# RL6955_IP_SVD register map
Vendor: Realtek
Registers are 32-bit, read-write, reset 0x0 unless marked. A register's access mark holds for its fields unless they carry their own. Offsets are from the block's base; [hi:lo] are bit positions; {n}, {i} and the like mark numbered series; <NAME> marks a mode.

## I3C_REG
Base 0x41890000
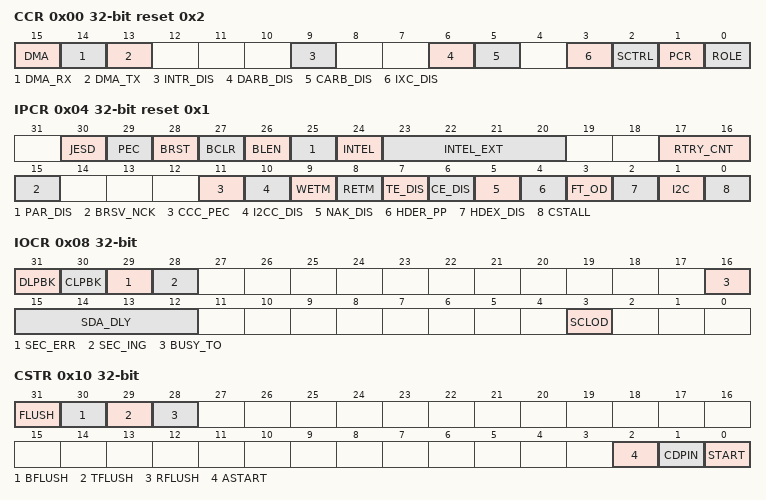
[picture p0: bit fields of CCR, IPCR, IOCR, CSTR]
0x00 CCR access per field reset 0x2 — Configuration Control Register
  [15] DMA wo — DMAC handshake interface support Exists: TAG >= 2.2.1
  [14] DMA_RX wo — DMAC handshake TX enable Exists: TAG >= 2.2.1
  [13] DMA_TX wo — DMAC handshake RX enable Exists: TAG >= 2.2.1
  [9] INTR_DIS rw — Interrupt global disable
  [6] DARB_DIS rw
  [5] CARB_DIS rw
  [3] IXC_DIS rw — IXC IP disable 1 = disable 0 = enable
  [2] SCTRL rw — Secondary Control mode enable for CCR.ROLE=TAGT.Only Can be set 1 when config I3CC_SCTRL = 1 in config form file, otherwise this bit would be always 0.
  [1] PCR rw — 1: Primary Control 0: Not Primary Control
  [0] ROLE rw — Role of the rxi356_i3cc Write: 0 - Role is the primary controller 1 - Role is the target Read: 0 - Role is the Active controller 1 - Role is the target
0x04 IPCR access per field reset 0x1 — I3C/I2C protocol control Register
  [30] JESD rw — JESD Spec enable
  [29] PEC rw — PEC CRC enable. Can be enable when INTEL = 1 or JESD =1 .
  [28] BRST rw — Bus Reset (TimedReset) enable. Can be enable when INTEL = 1 or JESD =1 .
  [27] BCLR rw — Bus Clear Enable. Can be enable when INTEL = 1 or JESD =1 .
  [26] BLEN rw — BL Enable for Intel Spec
  [25] PAR_DIS rw — Parity Check Disable (Can be disable when INTEL = 1 or JESD = 1).
  [24] INTEL rw — INTEL Spec enable
  [23:20] INTEL_EXT rw — Intel spec extend bit 23: intel_ddr : 0 (disable) / 1 (enable) bit 22: intel_as : 0 (disable) / 1 (enable) bit 21: intel_ccc : 0 (disable) / 1 (enable) bit 20: intel_ga : 0 (disable) / 1 (enable)
  [17:16] RTRY_CNT rw — Read Retry Count for ROLE = CTRL. RTRY_CNTretry numberTotal read cmd count 2'b00: No retry, total read cmd count=1 2'b01: Retry 1 time, total read cmd count=2 2'b10: Retry 2 times, total read cmd count=3 2'b11: Retry 3 times, total read cmd count=4
  [15] BRSV_NCK rw — Reserved
  [11] CCC_PEC rw — 1: Direct CCC cmd must includes pec byte, otherwise the pec_err & intr_pece would toggle. 0: disable this feature (just for INTEL = 1), direct CCC cmd without PEC byte would be acceptted as normal cmd, and the the pec_err & intr_pece would Not come out.
  [10] I2CC_DIS rw — for TAGT: NACK I2C private access. Maybe used in CTS 2.1.9 test.
  [9] WETM wo — Write Early terminate, not supported Now
  [8] RETM rw — Read Early terminate, not supported Now
  [7] TE_DIS rw — TAGT ERROR Disable
  [6] CE_DIS wo — CTRL ERROR Disable
  [5] NAK_DIS rw — RX NACK Disable
  [4] HDER_PP rw — Enable Header Address turn to PP timing
  [3] FT_OD rw — Force Timing = OD
  [2] HDEX_DIS rw — HDR EXIT Pattern Disable
  [1] I2C rw — I2C BUS enable
  [0] CSTALL rw — SCL STALL feature enable. Now always enable. (reserved)
0x08 IOCR — I/O Configuration Control Register
  [31] DLPBK — SDA loop back calibration function enable
  [30] CLPBK — SCL loop back calibration function enable
  [29] SEC_ERR — Indicated for I3C Secondary Controller Handoff Procedure occured an error.
  [28] SEC_ING — Indicated for I3C Secondary Controller Handoff Procedure is going.
  [16] BUSY_TO — Indicated to turn to idle phase when SCL, SDA hold for tIDLE
  [15:12] SDA_DLY — Indicated SDA delay count Valid value: 0~4; others reserved Exists: TAG >= 2.0.3
  [3] SCLOD — Force output: SCL in Open-Drain Status.
0x10 CSTR access per field — Control Structure register
  [31] FLUSH ro — Flush BYFM/TXDA/RXDA & recovery ixc status
  [30] BFLUSH ro — Flush BYFM FIFO
  [29] TFLUSH ro — Flush TXDA FIFO
  [28] RFLUSH ro — Flush RXDA/RCMD FIFO
  [2] ASTART rw — Control strucure async mode0 flow start
  [1] CDPIN rw — CDPin start Exists: TAG >= 2.0.2
  [0] START rw — Control strucure flow start
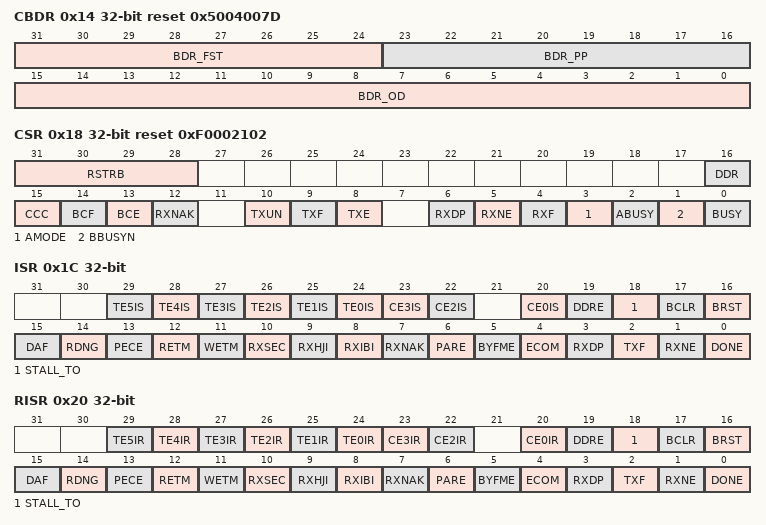
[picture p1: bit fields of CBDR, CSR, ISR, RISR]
0x14 CBDR reset 0x5004007D — SCL baud rate register
  [31:24] BDR_FST — Baud rate for the first header address
  [23:16] BDR_PP — Baud rate for PP
  [15:0] BDR_OD — Baud rate for OD
0x18 CSR access per field reset 0xF0002102 — Current Status Register
  [31:28] RSTRB ro — APB read strob Available value: 0x0, 0x1, 0x3, 0x7, 0xf
  [16] DDR ro — HDR-DDR mode
  [15] CCC ro — For target: receive a CCC cmd
  [14] BCF ro — BYFM CMD FIFO Full
  [13] BCE ro — BYFM CMD FIFO Empty
  [12] RXNAK ro — Received NACK
  [10] TXUN ro — TXDA Underflow (reserved)
  [9] TXF ro — TXDA Full
  [8] TXE ro — TXDA EMPTY
  [6] RXDP ro — RX DATA Drop
  [5] RXNE ro — RXDA Not Empty
  [4] RXF ro — RXDA Full
  [3] AMODE rw — In Async mode0 Only can be programmed in ctrl mode, user set AMODE=1 to enter asyn mode0 and set AMODE=0 to exit asyn mode0
  [2] ABUSY ro — 1: Async mode0 flow is still busy (action Not Over) 0: Async mode0 flow is Not busy
  [1] BBUSYN ro — BBUSYN = 1: IXC Bus is NOT Busy (Idle). Bus has detected Stop.BBUSYN= 0: IXC Bus is Busy. Bus has detected Start.
  [0] BUSY ro — 1: I3C/I2C transaction is still busy 0: I3C/I2C transaction is NOT busy (Idle)
0x1C ISR ro — Interrupt Status Register
  [n+24] TE{n}IS (n=0..5) — SDR target error type {n}
  [23] CE3IS — SDR controller error type 3
  [22] CE2IS — SDR controller error type 2
  [20] CE0IS — SDR controller error type 0
  [19] DDRE — DDR preamble, parity, CRC error
  [18] STALL_TO — For CTRL mode: SCL stall Timeout For TAGT mode: BUS busy Timeout
  [17] BCLR — Bus Clear
  [16] BRST — Bus Reset (TimedReset)
  [15] DAF — SDA arbitration fail
  [14] RDNG — Read RXDA word-unalign
  [13] PECE — PEC CRC Error
  [12] RETM — Read early terminate Occur
  [11] WETM — Write early terminate Occur
  [10] RXSEC — Receive Role REQ for ROLE=CTRL, or Received CCC GETACCCR for ROLE=SCTRL.
  [9] RXHJI — Receive Hot Join REQ
  [8] RXIBI — Receive IBI REQ
  [7] RXNAK — Receive NACK
  [6] PARE — PAR-bit Error For SDR mode: GETACCCR Format 3 (Role CTRL) ; TE1/2/3 For HDR mode: HDR-DDR transaction parity error
  [5] BYFME — BYFM Error
  [4] ECOM — Early COMplete transaction
  [3] RXDP — RX Data Drop occur for Role TAGT Case 1: Controller send write transcation with byte length exceed MWL. Case 2: Controller send write transcation meet RXDA_FIFO full
  [2] TXF — TXDA Full
  [1] RXNE — RXDA Not Empty
  [0] DONE — I3C/I2C transation is done
0x20 RISR ro — Raw Interrupt Status Register
  [n+24] TE{n}IR (n=0..5)
  [23] CE3IR
  [22] CE2IR
  [20] CE0IR
  [19] DDRE
  [18] STALL_TO
  [17] BCLR — Bus Clear
  [16] BRST — Bus Reset (TimedReset)
  [15] DAF
  [14] RDNG
  [13] PECE — PEC CRC Error
  [12] RETM
  [11] WETM
  [10] RXSEC
  [9] RXHJI
  [8] RXIBI
  [7] RXNAK
  [6] PARE
  [5] BYFME
  [4] ECOM
  [3] RXDP
  [2] TXF
  [1] RXNE
  [0] DONE
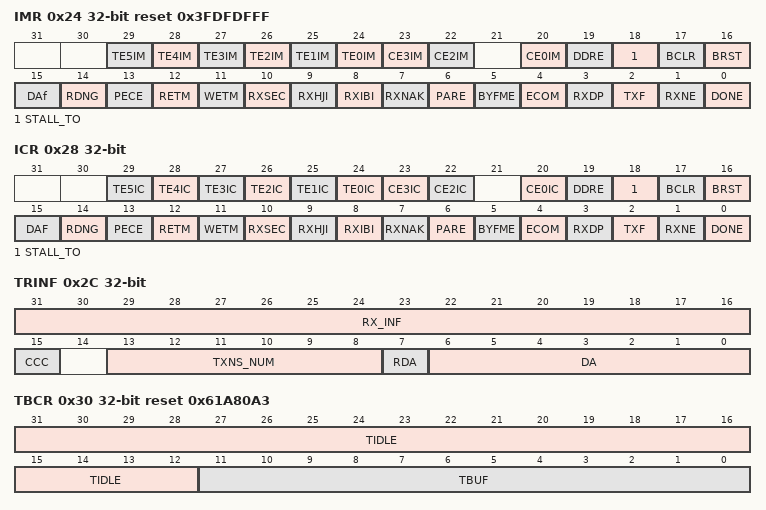
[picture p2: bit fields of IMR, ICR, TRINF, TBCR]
0x24 IMR reset 0x3FDFDFFF — Interrupt Mask Register
  [n+24] TE{n}IM (n=0..5)
  [23] CE3IM
  [22] CE2IM
  [20] CE0IM
  [19] DDRE
  [18] STALL_TO
  [17] BCLR — Bus Clear
  [16] BRST — Bus Reset (TimedReset)
  [15] DAf
  [14] RDNG
  [13] PECE — PEC CRC Error
  [12] RETM
  [11] WETM
  [10] RXSEC
  [9] RXHJI
  [8] RXIBI
  [7] RXNAK
  [6] PARE
  [5] BYFME
  [4] ECOM
  [3] RXDP
  [2] TXF
  [1] RXNE
  [0] DONE
0x28 ICR wo — Interrupt Clear Register
  [n+24] TE{n}IC (n=0..5)
  [23] CE3IC
  [22] CE2IC
  [20] CE0IC
  [19] DDRE
  [18] STALL_TO
  [17] BCLR — Bus Clear
  [16] BRST — Bus Reset (TimedReset)
  [15] DAF
  [14] RDNG
  [13] PECE — PEC CRC Error
  [12] RETM
  [11] WETM
  [10] RXSEC
  [9] RXHJI
  [8] RXIBI
  [7] RXNAK
  [6] PARE
  [5] BYFME
  [4] ECOM
  [3] RXDP
  [2] TXF
  [1] RXNE
  [0] DONE
0x2C TRINF ro — Transcation Information Register
  [31:16] RX_INF — [31:24]: for TAGT, receive CCC_CMD; for CTRL, receive IBI_MDB [23:16]: for TAGT, reveive CCC.defining byte; for CTRL, reserved
  [15] CCC — For target: receive a CCC cmd
  [13:8] TXNS_NUM — Transaction number for ROLE Ctrl
  [7] RDA — For TAGT, HDR-DDR req's RnW. For CTRL, IBI/HJ/SEC req's RnW.
  [6:0] DA — For TAGT, HDR-DDR command code. For CTRL, IBI/HJ/SEC req's DA.
0x30 TBCR reset 0x61A80A3 — BUS timing register
  [31:12] TIDLE — Bus IDLE Timing (tIDLE) count
  [11:0] TBUF — Bus Free Timing (tBUF) count
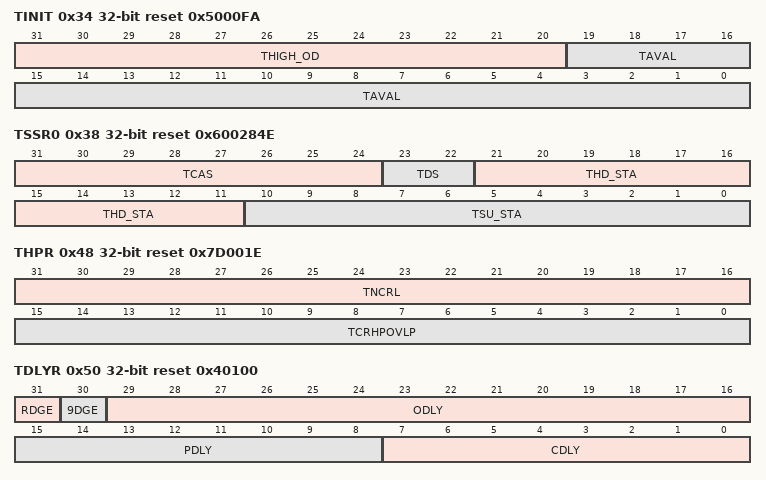
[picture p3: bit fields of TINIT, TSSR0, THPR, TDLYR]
0x34 TINIT reset 0x5000FA — Initial timing register
  [31:20] THIGH_OD — SCL High count for OD timing
  [19:0] TAVAL — Bus Available Timing (tAVAL) count
0x38 TSSR0 reset 0x600284E — Timing START register0
  [31:24] TCAS — tCAS timing count
  [23:22] TDS — tDS timing count Available value: 2'b00 ~ 2'b11
  [21:11] THD_STA — tHD_STA timing count
  [10:0] TSU_STA — tSU_STA timing count
0x3C TSSR1 reset 0x5 — Timing STOP register1
  [11:0] TSU_STO — tSU_STO timing count
0x40 TSTMR reset 0x30D4 — Reserved
  [31:0] TSTA_TO — Timeout count for pulling SCL=Low when SDA is Low at SEC HP flow.
0x44 TDR — Reserved
  [31:16] TSTALL_TO — Timeout count for SCL stall. Timeout = TSTALL_TO*32. Set 0 disable SCL stall timeout. ex. set 1 => timeout occur when counter count 32T
0x48 THPR reset 0x7D001E — Reserved
  [31:16] TNCRL — tNEWCRLock timing count
  [15:0] TCRHPOVLP — tCRHPOverlap timing count
0x4C THPTMR reset 0x30D4 — Reserved
  [15:0] TSDA_TO — Timeout count for pulling SDA=Low when SEC HP.
0x50 TDLYR reset 0x40100 — Timing delay register
  [31] RDGE — RX SDR data capture edge 0: high edge 1: low edge Only valid when cr_9dge set Exists: TAG >= 2.1.0
  [30] 9DGE — RX SDR data capture edge 0: data+9th(ack, T bit) capture at high edge cr_rhdy = 0; rx data: SDA before high edge according odly/pdly cr_rhdy = 1; rx data: SDA after high edge according odly/pdly 1: according CR_RDGE determine capture edge
  [29:16] ODLY — SDA Received delay count for header/data phase with OD mode
  [15:8] PDLY — SDA Received delay count for header/data phase with PP mode
  [7:0] CDLY — SCL Received delay count
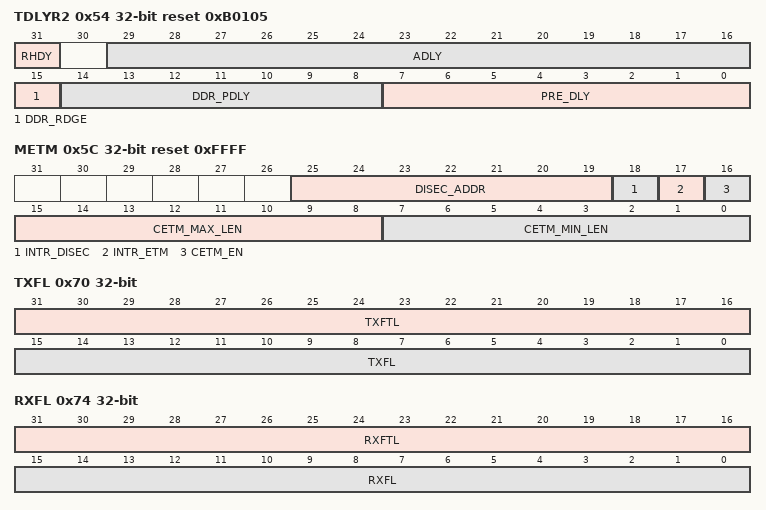
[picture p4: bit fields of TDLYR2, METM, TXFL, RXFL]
0x54 TDLYR2 reset 0xB0105 — Timing delay register2
  [31] RHDY — RX SDR data capture high edge with delay count 1: with delay count (ODLY/PDLY) 0: without delay count Exists: TAG >= 2.1.0
  [29:16] ADLY — SDA Received delay count for 9th of header/data phase with OD mode Exists: TAG >= 2.1.0
  [15] DDR_RDGE — Indicate capture point in DDR mode Rely on CR_DDR_PDLY to determine capture data/point 0: capture data at edge, data is according to DDR_PDLY DDR_PDLY= 0 => sda reg in delay 0T (sda_in_r) DDR_PDLY= 1 => sda reg in delay 1T (sda_in_r1) DDR_PDLY= 2 => sda reg in delay 2T (sda_in_r2) DDR_PDLY= 3 => sda reg in delay 3T (sda_in_r3) 1: capture data after edge with delay (delay is according to DDR_PDLY) Exists: TAG >= 2.1.0
  [14:8] DDR_PDLY — SDA Received delay count for DDR mode
  [7:0] PRE_DLY — The timing for SCL keep in low before preamble phase in DDR mode (min: BDR_PP)
0x58 TRST reset 0x60000 — Timing bus reset register
  [19:0] BRST — BUS reset timing count. Timeout = TSTALL_TO*64.
0x5C METM access per field reset 0xFFFF — Monitor early terminate register
  [25:19] DISEC_ADDR ro — The dynamic address of the TAGT which won BUS arbitration and not known to be a Monitoring Device
  [18] INTR_DISEC ro — Indicate the BUS arbitration was won by a TAGT not known to be a Monitoring Device User should disable this TAGT driven IBI
  [17] INTR_ETM ro — Indicate the previous transaction has been early terminated
  [16] CETM_EN rw — Enable CTRL early terminate feature to terminate long transactions
  [15:8] CETM_MAX_LEN rw — The maximum length of transaction that should be early terminated by CTRL The maximum length = 256 * (CETM_MIN_LEN + CETM_MAX_LEN), unit: CTRL clk cycle
  [7:0] CETM_MIN_LEN rw — The minimum length of transaction that should not be early terminated by CTRL The minimum length = 256 * CETM_MIN_LEN, unit: CTRL clk cycle
0x70 TXFL access per field — TXDA FIFO Level Register
  [31:16] TXFTL rw — Waterlevel for DMAC TX handshake If TXFTL = 0/1, I3CC only support single transcation; else, I3CC support burst + signle transcation (for DMAC flow, not I3C transcation). Available value: 0x0, 0x1, 0x4, 0x8, 0x16, ... (<= TDFR_DEPTH) Exist: Tag >= 2.2.1
  [15:0] TXFL ro — TXDA FIFO level
0x74 RXFL access per field — RXDA FIFO Level Register
  [31:16] RXFTL rw — Waterlevel for DMAC RX handshake If RXFTL = 0/1, I3CC only support single transcation; else, I3CC support burst + signle transcation (for DMAC flow, not I3C transcation). Available value: 0x0, 0x1, 0x4, 0x8, 0x16, ... (<= RDFR_DEPTH) Exist: Tag >= 2.2.1
  [15:0] RXFL ro — RXDA FIFO level
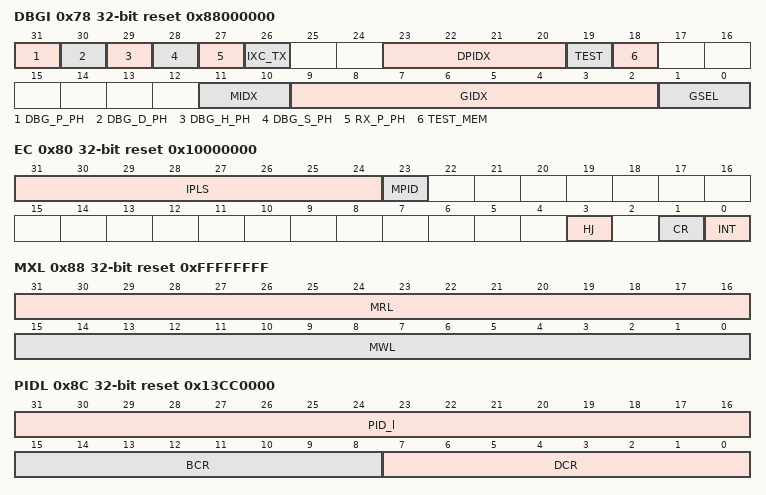
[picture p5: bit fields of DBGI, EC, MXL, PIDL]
0x78 DBGI access per field reset 0x88000000 — DBG Index Register
  [31] DBG_P_PH ro — Debug infomation P_PH
  [30] DBG_D_PH ro — Debug infomation D_PH
  [29] DBG_H_PH ro — Debug infomation H_PH
  [28] DBG_S_PH ro — Debug infomation S_PH
  [27] RX_P_PH ro — Debug information RX P_PH. If detect START, RX_P_PH = 0 If detect STOP, RX_P_PH =1
  [26] IXC_TX ro — 1 = IXC Send out SDA Data 0 = IXC Receive SDA Data
  [23:20] DPIDX wo — Debug Port Signal index Bit[3]: 1: TIC_DP 0: IXC_DP Bit[2:0]:Select 16 signals from total 64 signals.
  [19] TEST rw — Test mode enable (1 = enable, 0 = disable) Use a Vendor/Standard Extension - Direct CCCs to read/write access to rxi356_i3cc control registers
  [18] TEST_MEM rw — Data register enable (1 = enable (only when TEST = 1), 0 = disable) When enable, read/write will access to CR_MEM_DR, not FIFO.
  [11:10] MIDX rw — Index of MDB list groups 0x0: MDB index to 31~0 0x1: MDB index to 63~32 0x2: MDB index to 95~64 0x3: MDB index to 127~96
  [9:2] GIDX rw — Debug index of debug FIFO
  [1:0] GSEL rw — Debug access to BYFM/TXDA/BYFM/MDB 0x0: write access to MDB 0X1: read/write access to TXDA FIFO 0x2: read/write access to RXDA FIFO 0x3: read/write access to BYFM FIFO
0x7C DBGR — DBG Data Register
  [31:0] GDR
0x80 EC reset 0x10000000 — I3C Target Events Byte Register
  [31:24] IPLS — For TAGT: indicate IBI payload size for SETMRL/GETMRL. the thrid byte data if BCR[2] == 1 For CTRL: indicate IBI Payload Max size. If the IBI length > IPLS, CTRL would abort this IBI transaction.
  [23] MPID — Indicate I3C. PID[31:0] value is used from CR_PIDH and CR_PIDL If MPID == 1, I3C.PID[31:0] = \{CR_PIDH[15:0], CR_PIDL[31:16]} If MPID == 0, I3C.PID[31:0] = I3CC input port: user_pid_31_0 *. PID[47:0] = \{CRR_PIDH[31:0], CR_PIDL[31:16]} needs to following I3C.PID format If PID[32] == 1, PID[31:0] is vairable value
  [3] HJ — For TAGT: indicate Taget device. taget event[3] value 1: ENHJ by CCC: ENEC.taget event byte[3] 0: DISHJ by CCC: DISEC.taget event byte[3] For CTRL: If 1, then ACK Hot Join, and put interrupt rxhji. If 0, then NACK Hot Join.
  [1] CR — For TAGT: indicate Taget device. taget event[1] value 1: ENCR by CCC: ENEC.taget event byte[1] 0: DISCR by CCC: DISEC.taget event byte[1] For CTRL: If 1, then ACK Ctrl Role Req, and put interrupt rxsec. If 0, then NACK Ctrl Role Req.
  [0] INT — For TAGT: indicate Taget device. taget event[0] value 1: ENINT by CCC: ENEC.taget event byte[0] 0: DISINT by CCC: DISEC.taget event byte[0] For CTRL: If 1, then ACK IBI Req, and put interrupt rxibi and received the IBI payload if the TAGT send. If 0, then NACK IBI Req.
0x84 AS — Activity State Register
  [1:0] AS — Indicate Taget device. activity status Set value by CCC: ENTAS0~ENTAS3 ex: AS=0x1 written by ENTAS1 AS0: activity state 0; 1 us AS1: activity state 1; 100 us AS2: activity state 2; 2 ms AS3: activity state 3; 50 ms
0x88 MXL reset 0xFFFFFFFF — Max Write/Read Length Register
  [31:16] MRL — Indicated the max read length for SETMRL/GETMRL CR_MXL.MRL >= CR_MXL_MIN.MRL_MIN
  [15:0] MWL — Indicated the max read length for SETXWL/GETMWL CR_MXL.MWL >= CR_MXL_MIN.MWL_MIN
0x8C PIDL reset 0x13CC0000
  [31:16] PID_l — Indicated for I3C.PID[15:0]
  [15:8] BCR — Indicated for I3C.BCR
  [7:0] DCR — Indicated for I3C.DCR
0x90 PIDH
  [31:0] PID_H — Indicated for I3C.PID[47:16] *. Following I3C.PID format If PID[32] == 1, PID[31:0] is vairable value; default PID[31:0] = I3CC input port: user_pid_31_0
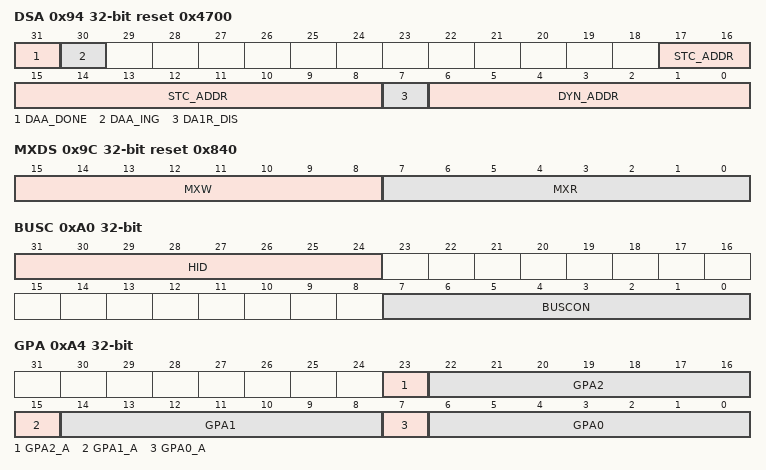
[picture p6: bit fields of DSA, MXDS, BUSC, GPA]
0x94 DSA access per field reset 0x4700 — Dynamic/Static Address Register
  [31] DAA_DONE ro — Indicated for I3C.dynamic address assignment (DAA) flow is done. If CR_DSA.DAA=1, it is indicated 1. Dynamic address is used for Taget address by SETDASA or ENTDAA. 2. Static address used for Taget address by SETAASA.
  [30] DAA_ING ro — Indicated for I3C.dynamic address assignment flow is going. It is set after ENTDAA command is executed.
  [17:8] STC_ADDR rw — Indicated Static address[6:0] for target addreess[6:0] Static address[17:8] for 10-bit Target addreess mode
  [7] DA1R_DIS rw — For DA = 0x1 (SETDASA format 2), Read/GETCCC ACK disable Exists: TAG >= 2.1.0
  [6:0] DYN_ADDR ro — Indicated Dynamic address[6:0] for Target addreess[6:0]
0x98 CCCST — Device Status (GETSTATUS) Register
  [15:0] STATUS — Indicate Target device current status Reply the value by CCC: GETSTATUS
0x9C MXDS reset 0x840 — Max Data Speed Register
  [15:8] MXW — Indicate Taget device. MXDS.MXR value; (defining byte support)transaction value by CCC: GETMXDS
  [7:0] MXR — Indicate Taget device. MXDS.MXR value Reply the value by CCC: GETMXDS Bit[6] Write-to-Read Permits Stop Between: private write / read with Sr are seperate transcations for IP.
0xA0 BUSC ro — BUS context Register
  [31:24] HID — Indicate target device receive. CCC.SETHID Exists: TAG >= 2.1.0
  [7:0] BUSCON — Indicate bus context Exists: TAG >= 2.1.0
0xA4 GPA ro — Group Address Register
  [23] GPA2_A — Group address 2 assigned Exists: TAG >= 2.1.0
  [22:16] GPA2 — Indicated Group address 2 for target
  [15] GPA1_A — Group address 1 assigned
  [14:8] GPA1 — Indicated Group address 1 for target
  [7] GPA0_A — Group address 0 assigned
  [6:0] GPA0 — Indicated Group address 0 for target
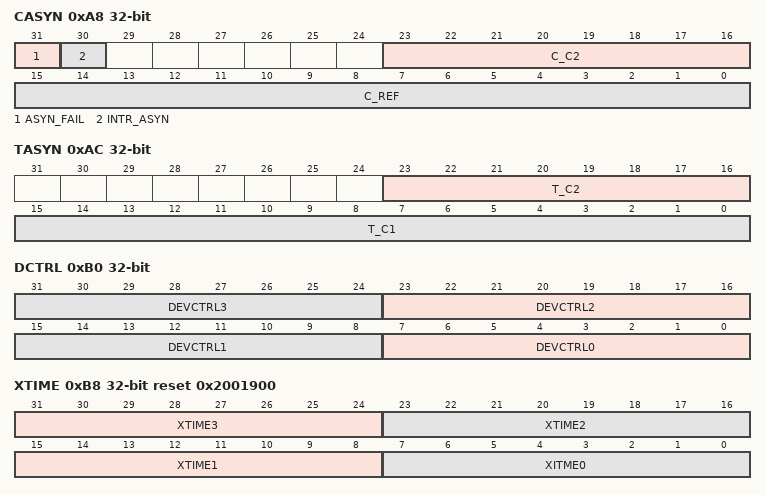
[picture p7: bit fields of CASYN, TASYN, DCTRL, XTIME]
0xA8 CASYN ro — Controller ASYN Timing Register
  [31] ASYN_FAIL — Indicate C_REF/C_C2 counter overflow
  [30] INTR_ASYN — Indicate ASYN IBI finished and inform user to read CASYN and TASYN
  [23:16] C_C2 — Controller counter from the first SCL positive-going edge after the IBI ACK to the first SCL positive-going edge after the T-Bit of the IBI's MDB
  [15:0] C_REF — Controller counter from IBI start to the first SCL positive-going edge after the IBI ACK
0xAC TASYN ro — Target ASYN Timing Register
  [23:16] T_C2 — Target counter from the first SCL positive-going edge after the IBI ACK to the first SCL positive-going edge after the T-Bit of the IBI's MDB
  [15:0] T_C1 — Target counter from IBI start to the first SCL positive-going edge after the IBI ACK
0xB0 DCTRL ro — DEVCTRL Register
  [8n+7:8n] DEVCTRL{n} (n=0..3) — Byte {n} Data payload for CCC.DEVCTRL; when IPCR.INTEL = 1 or JESD =1 Exists: TAG >= 2.1.0
0xB4 DCAP ro reset 0xFC — DEVCAP Register
  [15:0] DEVCAP — Data payload for CCC.DEVCAP Exists: TAG >= 2.1.0
0xB8 XTIME reset 0x2001900 — Exchange Timing Support Information Register
  [31:24] XTIME3 — Data byte (Supported Modes) for CCC.GETXTIME Exists: TAG >= 2.1.0
  [23:16] XTIME2 — Data byte (State) for CCC.GETXTIME Exists: TAG >= 2.1.0
  [15:8] XTIME1 — Data byte (Frequency) for CCC.GETXTIME Exists: TAG >= 2.1.0
  [7:0] XITME0 — Data byte (Inaccuracy) for CCC.GETXTIME Exists: TAG >= 2.1.0
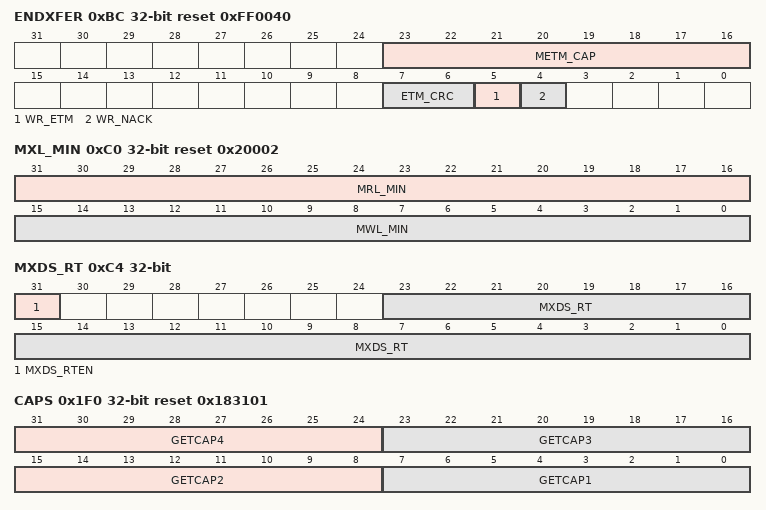
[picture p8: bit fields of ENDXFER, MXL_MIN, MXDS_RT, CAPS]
0xBC ENDXFER reset 0xFF0040 — ENDXFER Early Termination Parameters Register
  [23:16] METM_CAP — Indicate Monitoring Device Early Termination Capability 8'hff: Disable all 8'h01: Enable on SDR 8'hfe: Disable on SDR 8'h02: Enable on HDR-DDR 8'hfd: Disable on HDR-DDR Other settings are not supported Exists: TAG >= 2.1.0
  [7:6] ETM_CRC — 2'b11: No CRC Word follows Early Termination request 2'b01: CRC Word follows Early Termination Exists: TAG >= 2.1.0
  [5] WR_ETM — Enable HDR WRITE Early Termination Request 1'b0: Enable 1'b1: Disable Exists: TAG >= 2.1.0
  [4] WR_NACK — Enable ACK/NACK Capability for WRITE Command 1'b0: Enable 1'b1: Disable Exists: TAG >= 2.1.0
0xC0 MXL_MIN reset 0x20002 — MRL/MRL defined Minimum value
  [31:16] MRL_MIN — MRL defined minimum value
  [15:0] MWL_MIN — MWL defined minimum value
0xC4 MXDS_RT — Max Data ReadTurn Register
  [31] MXDS_RTEN — 1'b1: IP will provide 3-byte RdTurn for CCC.GETMXDS 1'b0: No MaxRdTurn Bytes Exists: TAG >= 2.1.0
  [23:0] MXDS_RT — 3-byte MaxRdTurn
0xC8 RSTACT
  [31:0] RSTACT — [31:24]: to store the defining byte previously received in Direct SET (contain 0x0-0x4). (auto_clear when receiving Start, not Sr) data for CCC.RSTACT direct get with def_byte = 0x0-0x3, 0x80 [23:16]: data for CCC.RSTACT direct get with def_byte = 0x83 (reserved) [15:8]: data for CCC.RSTACT direct get with def_byte = 0x82 [7:0]: data for CCC.RSTACT direct get with def_byte = 0x81 Exists: TAG >= 2.1.0
0xE0 MEM_DR — Data register 0
  [31:0] MEM_DR — If CR_DBGI.CR_TEST = 1 && CR_DBGI.CR_TEST_MEM = 1, then enable mem-type read/write For private write, I3CC will update data from byte 0 to byte 3, other byte will be dropped (register index is needed, don't care about index value). For private read, I3CC will proivide data from byte 0 to byte 3 (length default is 4, can be set to 1/2/3 by CCC.SETMRL)
0xEC RW_CMD ro reset 0xEF — Vendor Direct CCC for access to CRs
  [7:0] RW_CMD — The code for Vender - Direct CCCs read/write access to CRs Exists: TAG >= 2.1.0
0xFC MDB — MDB list Register
  [31:0] MDB — Indicate the index of MDB list to read/write the MDB information of the each Target device for Control device mode
{0x100+4i} CFR{i} wo (i=0..15) — Control BYFM FIFO Register
  [31:0] BYFM_FIFO_{i} — BYFM FIFO index register to write 4-byte data toBYFM FIFO used to program I3C/I2C transaction operations. Support fixed or increased address. And max addess is to write 64 byte data (<= config:TXDA_DEPTH /4) ex: 1. Fixed address: 0x100 to read data of BYFM FIFO 2. Increased address: 0x100~(0x100 +BYFM FIFO Depth/4 ) to write data of BYFM FIFO
{0x140+4i} TBDFR{i} wo (i=0..15) — Byte-access TXDA FIFO register
  [31:0] TXDA_FIFO_{i} — Tag <= 2.2.0 TXDA FIFO index register to write 1/2/4-byte data. Tag >= 2.2.1 TXDA FIFO index register to wirte 0/1-byte data TXDA FIFO is used to program I3C/I2C transaction data. Support fixed or increased address. ex: 1. Fixed address: 0x140 to write data into TXDA FIFO 2. Increased address: 0x140~ 0x17C to write data into TXDA FIFO
{0x180+4i} RBDFR{i} ro (i=0..15) — Byte-access RXDA FIFO register
  [31:0] RXDA_FIFO_{i} — Tag <= 2.2.0 RXDA FIFO index register to read 4-byte data. Tag >= 2.2.1 RXDA FIFO index register to read 1-byte data. RXDA FIFO is used to read I3C/I2C recevied data. Support fixed or increased address. ex: 1. Fixed address: 0x180 to read data from RXDA FIFO 2. Increased address: 0x180~0x1BC to read data from RXDA FIFO
0x1F0 CAPS ro reset 0x183101 — Capabilities register
  [31:24] GETCAP4 — Reserved
  [23:16] GETCAP3 — [20] = 1: Defining Byte Support in GETSTATUS [19] = 1: Defining Byte Support in GETCAPS
  [15:8] GETCAP2 — [13:12] = 3: Group Address Capabilities , can be assigned three Group address [11:8] = 1: I3C 1.x Specification Version = V1.1 Exists: TAG >= 2.1.0
  [7:0] GETCAP1 — [0] = 1: HDR Mode; 0: HDR-DDR Exists: TAG >= 2.1.0
0x1F8 GIT ro — GIT num register
  [31:0] TAG_NUM — Indicate the commit number of the released RTL code ex: tag 2.0.1 GIT_NUM = 0x00_02_00_01
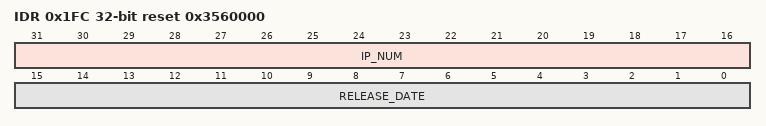
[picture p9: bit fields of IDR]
0x1FC IDR ro reset 0x3560000 — Identification Register
  [31:16] IP_NUM
  [15:0] RELEASE_DATE — Indicate the IP release date for the particular project ex: the released date is 01/26, ELEASE_DAT =0x0126
{0x240+4i} TWDFR{i} wo (i=0..15) — Word-access TXDA FIFO register
  [31:0] TXDA_FIFO_{i} — TXDA FIFO index register to write 0/1/2/4-byte data. Default: 4-byte data, also support 0/1/2-byte data, decided by APB.PSTRB[3:0] TXDA FIFO is used to program I3C/I2C transaction data. Support fixed or increased address. ex: 1. Fixed address: 0x240 to write data into TXDA FIFO 2. Increased address: 0x240~ 0x27C to write data into TXDA FIFO Exist: Tag >= 2.2.1
{0x280+4i} RWDFR{i} ro (i=0..15) — Word-access RXDA FIFO register
  [31:0] RXDA_FIFO_{i} — RXDA FIFO index register to read 4-byte data. Default: 4-byte data, also support pop 0-3 byte data when RXDA empty meets BUS/I3CC IDLE RXDA FIFO is used to read I3C/I2C recevied data. Support fixed or increased address. ex: 1. Fixed address: 0x280 to read data from RXDA FIFO 2. Increased address: 0x280~0x2BC to read data from RXDA FIFO
